# GD32L23x register map
File version: 1.0
CPU: CM23 r0p0, little endian, MPU, FPU, 4 interrupt priority bits
Registers are 32-bit, read-write, reset 0x0 unless marked. A register's access mark holds for its fields unless they carry their own. Offsets are from the block's base; [hi:lo] are bit positions; {n}, {i} and the like mark numbered series.

## PMU — Power management unit
Base 0x40007000
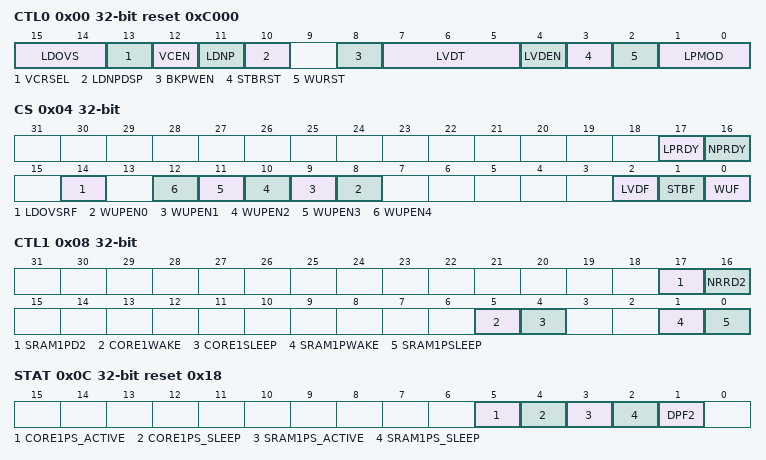
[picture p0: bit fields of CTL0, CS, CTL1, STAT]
0x00 CTL0 reset 0xC000 — power control register 0
  [15:14] LDOVS — LDO output voltage select
  [13] VCRSEL — VBAT battery charging resistor selection
  [12] VCEN — VBAT battery charging enable
  [11] LDNP — Low-driver mode when use normal power LDO in Run/Sleep mode
  [10] LDNPDSP — Low-driver mode when use normal power LDO in Deep-sleep mode
  [8] BKPWEN — Backup Domain Write Enable
  [7:5] LVDT — Low Voltage Detector Threshold
  [4] LVDEN — Low Voltage Detector Enable
  [3] STBRST — Standby Flag Reset
  [2] WURST — Wakeup Flag Reset
  [1:0] LPMOD — Select the lowpower mode to enter
0x04 CS access per field — power control/status register
  [17] LPRDY rw — Lowpower LDO ready flag
  [16] NPRDY rw — Normal power LDO ready flag
  [14] LDOVSRF rw — LDO voltage select ready flag
  [n+8] WUPEN{n} rw (n=0..4) — WKUP pin{n} Enable
  [2] LVDF ro — Low Voltage Detector Status Flag
  [1] STBF ro — Standby flag
  [0] WUF ro — Wakeup flag
0x08 CTL1 — power control register 1
  [17] SRAM1PD2 — Power state of 16KB SRAM when enter s Deep sleep2 mode
  [16] NRRD2 — No retention register in Deepsleep 2 mode
  [5] CORE1WAKE — COREOFF1 domain wakeup
  [4] CORE1SLEEP — COREOFF1 domain go to power-off
  [1] SRAM1PWAKE — 16KB SRAM wakeup
  [0] SRAM1PSLEEP — 16KB SRAM go to power off
0x0C STAT reset 0x18 — power Status register (PMU_
  [5] CORE1PS_ACTIVE — COREOFF1 domain is in active state
  [4] CORE1PS_SLEEP — COREOFF1 domain is in sleep state
  [3] SRAM1PS_ACTIVE — SRAM1 is in active state
  [2] SRAM1PS_SLEEP — SRAM1 is in sleep state
  [1] DPF2 — This bit is Deep-sleep2 mode status
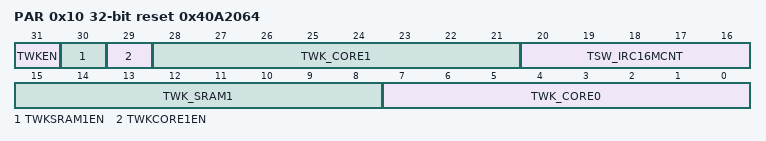
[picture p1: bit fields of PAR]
0x10 PAR reset 0x40A2064 — Parameter register
  [31] TWKEN — Use software value when wake up Deep-sleep2 or not
  [30] TWKSRAM1EN — Use software value when wake up SRAM1 power domain or not
  [29] TWKCORE1EN — Use software value when wake up COREOFF1 or not
  [28:21] TWK_CORE1 — Wakeup time of power switch of COREOFF1 domain
  [20:16] TSW_IRC16MCNT — When enter deep-sleep mode, switch to IRC16M clock
  [15:8] TWK_SRAM1 — Wakeup time of power switch of SRAM1 domain
  [7:0] TWK_CORE0 — Wakeup time of power switch of COREOFF0 domain

## WWDGT — Window watchdog timer
Base 0x40002C00
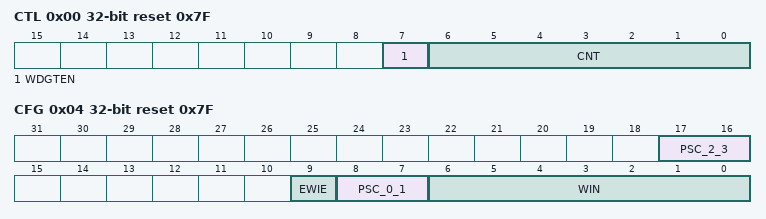
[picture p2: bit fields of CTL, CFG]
0x00 CTL reset 0x7F — Control register
  [7] WDGTEN — Activation bit
  [6:0] CNT — 7-bit counter
0x04 CFG reset 0x7F — Configuration register
  [17:16] PSC_2_3 — Prescaler
  [9] EWIE — Early wakeup interrupt
  [8:7] PSC_0_1 — Prescaler
  [6:0] WIN — 7-bit window value
0x08 STAT — Status register
  [0] EWIF — Early wakeup interrupt flag

## DAC — Digital-to-analog converter
Base 0x40007400
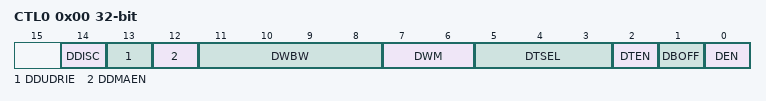
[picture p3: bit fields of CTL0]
0x00 CTL0 — control register 0
  [14] DDISC — DAC_OUT connect GPIO selection
  [13] DDUDRIE — DAC_OUT DMA underrun interrupt enable
  [12] DDMAEN — DAC DMA enable
  [11:8] DWBW — DAC noise wave bit width
  [7:6] DWM — DAC noise wave mode
  [5:3] DTSEL — DAC trigger selection
  [2] DTEN — DAC trigger enable
  [1] DBOFF — DAC output buffer turn off
  [0] DEN — DAC enable
0x04 SWT wo — software trigger register
  [0] SWTR — DAC software trigger
0x08 OUT_R12DH — DAC_OUT 12-bit right-aligned data holding register
  [11:0] OUT_DH — DAC_OUT 12-bit right-aligned data
0x0C OUT_L12DH — DAC_OUT 12-bit left-aligned data holding register
  [15:4] OUT_DH — DAC_OUT 12-bit left-aligned data
0x10 OUT_R8DH — DAC_OUT 8-bit right aligned data holding register
  [7:0] OUT_DH — DAC_OUT 8-bit right-aligned data
0x14 OUT_DO ro — DAC_OUT data output register (OUT_DO)
  [11:0] OUT_DO — DAC_OUT data output
0x18 DAC_STAT0 — DAC S tatus register 0
  [13] DDUDR — DAC_OUT DMA underrun flag

## TRNG — Ture random number generator
Base 0x50060800
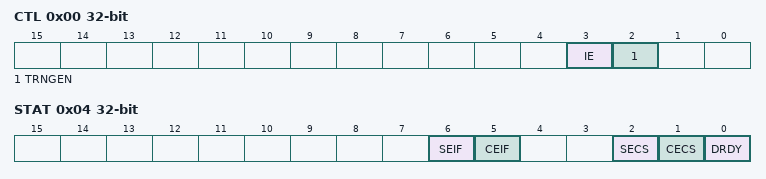
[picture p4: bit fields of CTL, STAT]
0x00 CTL — Control register
  [3] IE — Interrupt bit
  [2] TRNGEN — TRNG enable bit
0x04 STAT access per field — Status register
  [6] SEIF rw — Seed error interrupt flag
  [5] CEIF rw — Clock error interrupt flag
  [2] SECS ro — Seed error current status
  [1] CECS ro — Clock error current status
  [0] DRDY ro — Random data ready status bit
0x08 DATA ro
  [31:0] TRNDATA — 32-bit random data
